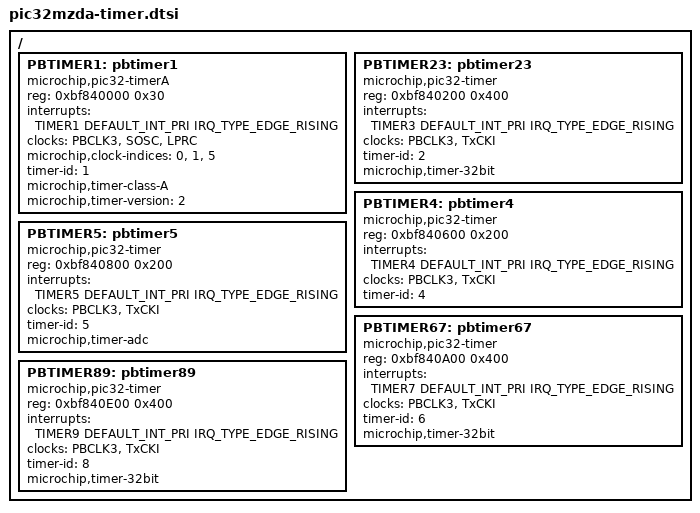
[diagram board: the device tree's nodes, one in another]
/*
 * Device Tree Source for PIC32MZ (DA) General Purpose Periheral Timer
 *
 * Copyright (C) 2014 Microchip Technology, Inc.
 *               2014 Purna Chandra Mandal <purna.mandal@microchip.com>
 *
 * Licensed under GPLv2 or later.
 */

/ {
	/* 16-bit class-a timer */
	PBTIMER1:pbtimer1 {
		#timer-cells = <0>;
		reg = <0xbf840000 0x30>;
		compatible = "microchip,pic32-timerA";
		interrupts = <TIMER1 DEFAULT_INT_PRI IRQ_TYPE_EDGE_RISING>;
		clocks = <&PBCLK3>, <&SOSC>,/*<&TxCKI>,*/<&LPRC>;
		microchip,clock-indices = <0>, <1>, /*<3>, */<5>;
		timer-id = <1>;
		microchip,timer-class-A;  /* class A timer */
		microchip,timer-version = <2>; /* v2 timer */
	};

	/* 32-bit class-b timer */
	PBTIMER23:pbtimer23 {
		#timer-cells = <0>;
		compatible = "microchip,pic32-timer";
		reg = <0xbf840200 0x400>;
		interrupts = <TIMER3 DEFAULT_INT_PRI IRQ_TYPE_EDGE_RISING>;
		clocks = <&PBCLK3>, <&TxCKI>;
		timer-id = <2>;
		microchip,timer-32bit;   /* class B, 32-bit combined timer */
	};

	/* 16-bit class-b timer */
	PBTIMER4:pbtimer4 {
		#timer-cells = <0>;
		compatible = "microchip,pic32-timer";
		reg = <0xbf840600 0x200>;
		interrupts = <TIMER4 DEFAULT_INT_PRI IRQ_TYPE_EDGE_RISING>;
		clocks = <&PBCLK3>, <&TxCKI>;
		timer-id = <4>;
	};

	/* 16-bit class-b timer */
	PBTIMER5:pbtimer5 {
		#timer-cells = <0>;
		compatible = "microchip,pic32-timer";
		reg = <0xbf840800 0x200>;
		interrupts = <TIMER5 DEFAULT_INT_PRI IRQ_TYPE_EDGE_RISING>;
		clocks = <&PBCLK3>, <&TxCKI>;
		timer-id = <5>;
		microchip,timer-adc; /* can trigger ADC on match */
	};

	/* 32-bit class-b timer */
	PBTIMER67:pbtimer67 {
		#timer-cells = <0>;
		compatible = "microchip,pic32-timer";
		reg = <0xbf840A00 0x400>;
		interrupts = <TIMER7 DEFAULT_INT_PRI IRQ_TYPE_EDGE_RISING>;
		clocks = <&PBCLK3>, <&TxCKI>;
		timer-id = <6>;
		microchip,timer-32bit;
	};

	/* 32-bit class-b timer */
	PBTIMER89:pbtimer89 {
		#timer-cells = <0>;
		compatible = "microchip,pic32-timer";
		reg = <0xbf840E00 0x400>;
		interrupts = <TIMER9 DEFAULT_INT_PRI IRQ_TYPE_EDGE_RISING>;
		clocks = <&PBCLK3>, <&TxCKI>;
		timer-id = <8>;
		microchip,timer-32bit;
	};
};
